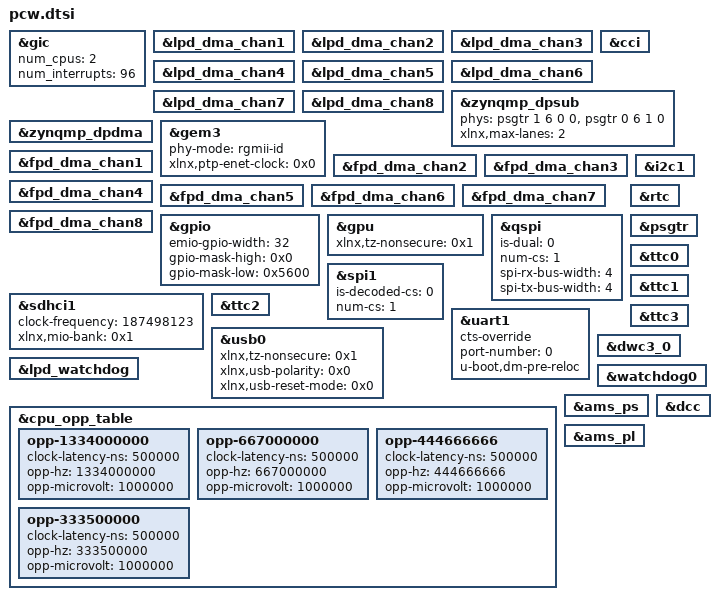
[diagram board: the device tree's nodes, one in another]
/*
 * CAUTION: This file is automatically generated by Xilinx.
 * Version: XSCT 2025.1
 * Today is: Sun Aug 30 14:09:04 2026
 */


&gic {
	num_cpus = <2>;
	num_interrupts = <96>;
};
&lpd_dma_chan1 {
	status = "okay";
};
&lpd_dma_chan2 {
	status = "okay";
};
&lpd_dma_chan3 {
	status = "okay";
};
&lpd_dma_chan4 {
	status = "okay";
};
&lpd_dma_chan5 {
	status = "okay";
};
&lpd_dma_chan6 {
	status = "okay";
};
&lpd_dma_chan7 {
	status = "okay";
};
&lpd_dma_chan8 {
	status = "okay";
};
&cci {
	status = "okay";
};
&zynqmp_dpsub {
	phy-names = "dp-phy0","dp-phy1";
	phys = <&psgtr 1 6 0 0>, <&psgtr 0 6 1 0>;
	status = "okay";
	xlnx,max-lanes = <2>;
};
&zynqmp_dpdma {
	status = "okay";
};
&gem3 {
	phy-mode = "rgmii-id";
	status = "okay";
	xlnx,ptp-enet-clock = <0x0>;
};
&fpd_dma_chan1 {
	status = "okay";
};
&fpd_dma_chan2 {
	status = "okay";
};
&fpd_dma_chan3 {
	status = "okay";
};
&fpd_dma_chan4 {
	status = "okay";
};
&fpd_dma_chan5 {
	status = "okay";
};
&fpd_dma_chan6 {
	status = "okay";
};
&fpd_dma_chan7 {
	status = "okay";
};
&fpd_dma_chan8 {
	status = "okay";
};
&gpio {
	emio-gpio-width = <32>;
	gpio-mask-high = <0x0>;
	gpio-mask-low = <0x5600>;
	status = "okay";
};
&gpu {
	status = "okay";
	xlnx,tz-nonsecure = <0x1>;
};
&i2c1 {
	status = "okay";
};
&qspi {
	is-dual = <0>;
	num-cs = <1>;
	spi-rx-bus-width = <4>;
	spi-tx-bus-width = <4>;
	status = "okay";
};
&rtc {
	status = "okay";
};
&sdhci1 {
	clock-frequency = <187498123>;
	status = "okay";
	xlnx,mio-bank = <0x1>;
};
&psgtr {
	status = "okay";
};
&spi1 {
	is-decoded-cs = <0>;
	num-cs = <1>;
	status = "okay";
};
&ttc0 {
	status = "okay";
};
&ttc1 {
	status = "okay";
};
&ttc2 {
	status = "okay";
};
&ttc3 {
	status = "okay";
};
&uart1 {
	cts-override ;
	device_type = "serial";
	port-number = <0>;
	status = "okay";
	u-boot,dm-pre-reloc ;
};
&usb0 {
	status = "okay";
	xlnx,tz-nonsecure = <0x1>;
	xlnx,usb-polarity = <0x0>;
	xlnx,usb-reset-mode = <0x0>;
};
&dwc3_0 {
	status = "okay";
};
&lpd_watchdog {
	status = "okay";
};
&watchdog0 {
	status = "okay";
};
&cpu_opp_table {
	/delete-node/ opp00 ;
	/delete-node/ opp01 ;
	/delete-node/ opp02 ;
	/delete-node/ opp03 ;
	opp-1334000000 {
		clock-latency-ns = <500000>;
		opp-hz = /bits/ 64 <1334000000>;
		opp-microvolt = <1000000>;
	};
	opp-667000000 {
		clock-latency-ns = <500000>;
		opp-hz = /bits/ 64 <667000000>;
		opp-microvolt = <1000000>;
	};
	opp-444666666 {
		clock-latency-ns = <500000>;
		opp-hz = /bits/ 64 <444666666>;
		opp-microvolt = <1000000>;
	};
	opp-333500000 {
		clock-latency-ns = <500000>;
		opp-hz = /bits/ 64 <333500000>;
		opp-microvolt = <1000000>;
	};
};
&ams_ps {
	status = "okay";
};
&ams_pl {
	status = "okay";
};
&dcc {
	status = "okay";
};
